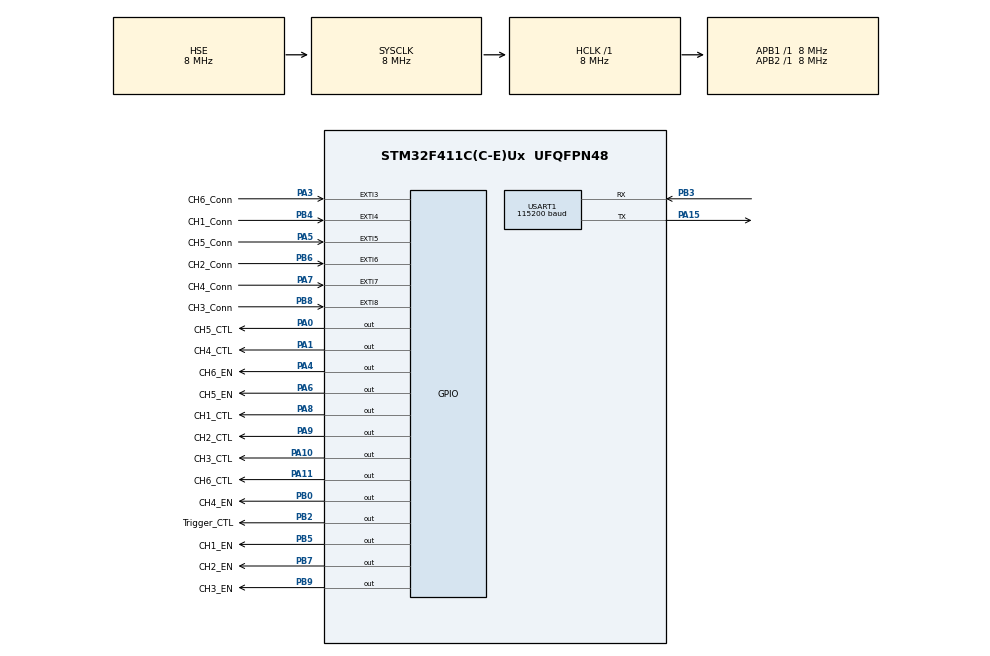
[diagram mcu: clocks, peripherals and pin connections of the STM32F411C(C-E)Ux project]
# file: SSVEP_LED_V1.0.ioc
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Mcu.Family=STM32F4
Mcu.Name=STM32F411C(C-E)Ux
Mcu.Package=UFQFPN48
NVIC.PriorityGroup=NVIC_PRIORITYGROUP_4
NVIC.TIM1_BRK_TIM9_IRQn=true\:2\:0\:true\:false\:true\:true\:true\:true
NVIC.TIM1_TRG_COM_TIM11_IRQn=true\:2\:0\:true\:false\:true\:true\:true\:true
NVIC.TIM1_UP_TIM10_IRQn=true\:2\:0\:true\:false\:true\:true\:true\:true
NVIC.TIM3_IRQn=true\:2\:0\:true\:false\:true\:true\:true\:true
NVIC.TIM4_IRQn=true\:2\:0\:true\:false\:true\:true\:true\:true
NVIC.TIM5_IRQn=true\:2\:0\:true\:false\:true\:true\:true\:true
NVIC.USART1_IRQn=true\:1\:0\:true\:false\:true\:true\:true\:true
PA0-WKUP.GPIO_Label=CH5_CTL
PA0-WKUP.GPIO_PuPd=GPIO_NOPULL
PA0-WKUP.GPIO_Speed=GPIO_SPEED_FREQ_VERY_HIGH
PA0-WKUP.PinState=GPIO_PIN_RESET
PA0-WKUP.Signal=GPIO_Output
PA1.GPIO_Label=CH4_CTL
PA1.GPIO_PuPd=GPIO_NOPULL
PA1.GPIO_Speed=GPIO_SPEED_FREQ_VERY_HIGH
PA1.Signal=GPIO_Output
PA10.GPIO_Label=CH3_CTL
PA10.GPIO_PuPd=GPIO_NOPULL
PA10.GPIO_Speed=GPIO_SPEED_FREQ_VERY_HIGH
PA10.Signal=GPIO_Output
PA11.GPIO_Label=CH6_CTL
PA11.GPIO_PuPd=GPIO_NOPULL
PA11.GPIO_Speed=GPIO_SPEED_FREQ_VERY_HIGH
PA11.Signal=GPIO_Output
PA13.Mode=Serial_Wire
PA13.Signal=SYS_JTMS-SWDIO
PA14.Mode=Serial_Wire
PA14.Signal=SYS_JTCK-SWCLK
PA15.Mode=Asynchronous
PA15.Signal=USART1_TX
PA3.GPIO_Label=CH6_Conn
PA3.GPIO_ModeDefaultEXTI=GPIO_MODE_IT_RISING_FALLING
PA3.GPIO_PuPd=GPIO_PULLUP
PA3.Signal=GPXTI3
PA4.GPIO_Label=CH6_EN
PA4.GPIO_PuPd=GPIO_PULLUP
PA4.GPIO_Speed=GPIO_SPEED_FREQ_HIGH
PA4.PinState=GPIO_PIN_SET
PA4.Signal=GPIO_Output
PA5.GPIO_Label=CH5_Conn
PA5.GPIO_ModeDefaultEXTI=GPIO_MODE_IT_RISING_FALLING
PA5.GPIO_PuPd=GPIO_PULLUP
PA5.Signal=GPXTI5
PA6.GPIO_Label=CH5_EN
PA6.GPIO_PuPd=GPIO_PULLUP
PA6.GPIO_Speed=GPIO_SPEED_FREQ_HIGH
PA6.PinState=GPIO_PIN_SET
PA6.Signal=GPIO_Output
PA7.GPIO_Label=CH4_Conn
PA7.GPIO_ModeDefaultEXTI=GPIO_MODE_IT_RISING_FALLING
PA7.GPIO_PuPd=GPIO_PULLUP
PA7.Signal=GPXTI7
PA8.GPIO_Label=CH1_CTL
PA8.GPIO_PuPd=GPIO_NOPULL
PA8.GPIO_Speed=GPIO_SPEED_FREQ_VERY_HIGH
PA8.Signal=GPIO_Output
PA9.GPIO_Label=CH2_CTL
PA9.GPIO_PuPd=GPIO_NOPULL
PA9.GPIO_Speed=GPIO_SPEED_FREQ_VERY_HIGH
PA9.Signal=GPIO_Output
PB0.GPIO_Label=CH4_EN
PB0.GPIO_PuPd=GPIO_PULLUP
PB0.GPIO_Speed=GPIO_SPEED_FREQ_HIGH
PB0.PinState=GPIO_PIN_SET
PB0.Signal=GPIO_Output
PB2.GPIO_Label=Trigger_CTL
PB2.GPIO_PuPd=GPIO_PULLDOWN
PB2.GPIO_Speed=GPIO_SPEED_FREQ_VERY_HIGH
PB2.Signal=GPIO_Output
PB3.Mode=Asynchronous
PB3.Signal=USART1_RX
PB4.GPIO_Label=CH1_Conn
PB4.GPIO_ModeDefaultEXTI=GPIO_MODE_IT_RISING_FALLING
PB4.GPIO_PuPd=GPIO_PULLUP
PB4.Signal=GPXTI4
PB5.GPIO_Label=CH1_EN
PB5.GPIO_PuPd=GPIO_PULLUP
PB5.GPIO_Speed=GPIO_SPEED_FREQ_HIGH
PB5.PinState=GPIO_PIN_SET
PB5.Signal=GPIO_Output
PB6.GPIO_Label=CH2_Conn
PB6.GPIO_ModeDefaultEXTI=GPIO_MODE_IT_RISING_FALLING
PB6.GPIO_PuPd=GPIO_PULLUP
PB6.Signal=GPXTI6
PB7.GPIO_Label=CH2_EN
PB7.GPIO_PuPd=GPIO_PULLUP
PB7.GPIO_Speed=GPIO_SPEED_FREQ_HIGH
PB7.PinState=GPIO_PIN_SET
PB7.Signal=GPIO_Output
PB8.GPIO_Label=CH3_Conn
PB8.GPIO_ModeDefaultEXTI=GPIO_MODE_IT_RISING_FALLING
PB8.GPIO_PuPd=GPIO_PULLUP
PB8.Signal=GPXTI8
PB9.GPIO_Label=CH3_EN
PB9.GPIO_PuPd=GPIO_PULLUP
PB9.GPIO_Speed=GPIO_SPEED_FREQ_HIGH
PB9.PinState=GPIO_PIN_SET
PB9.Signal=GPIO_Output
PH0\ -\ OSC_IN.Mode=HSE-External-Oscillator
PH0\ -\ OSC_IN.Signal=RCC_OSC_IN
PH1\ -\ OSC_OUT.Mode=HSE-External-Oscillator
PH1\ -\ OSC_OUT.Signal=RCC_OSC_OUT
ProjectManager.HeapSize=0x200
ProjectManager.StackSize=0x400
ProjectManager.TargetToolchain=MDK-ARM V5.32
RCC.48MHZClocksFreq_Value=25000000
RCC.AHBFreq_Value=8000000
RCC.APB1Freq_Value=8000000
RCC.APB1TimFreq_Value=8000000
RCC.APB2Freq_Value=8000000
RCC.APB2TimFreq_Value=8000000
RCC.CortexFreq_Value=8000000
RCC.HCLKFreq_Value=8000000
RCC.HSE_VALUE=8000000
RCC.HSI_VALUE=16000000
RCC.LSE_VALUE=32768
RCC.PLLM=8
RCC.PLLN=100
RCC.PLLSourceVirtual=RCC_PLLSOURCE_HSE
RCC.SYSCLKFreq_VALUE=8000000
RCC.SYSCLKSource=RCC_SYSCLKSOURCE_HSE
RCC.VCOOutputFreq_Value=100000000
TIM10.Prescaler=1220-1
TIM11.Prescaler=1220-1
TIM3.AutoReloadPreload=TIM_AUTORELOAD_PRELOAD_DISABLE
TIM3.ClockDivision=TIM_CLOCKDIVISION_DIV1
TIM3.Period=65535
TIM3.Prescaler=1220-1
TIM3.TIM_MasterOutputTrigger=TIM_TRGO_OC1
TIM4.Prescaler=1220-1
TIM4.TIM_MasterOutputTrigger=TIM_TRGO_OC1
TIM5.Period=65535
TIM5.Prescaler=1220-1
TIM5.TIM_MasterOutputTrigger=TIM_TRGO_OC1
TIM9.Prescaler=1220-1
USART1.BaudRate=115200
USART1.VirtualMode=VM_ASYNC
VP_TIM10_VS_ClockSourceINT.Mode=Enable_Timer
VP_TIM11_VS_ClockSourceINT.Mode=Enable_Timer
VP_TIM3_VS_ClockSourceINT.Mode=Internal
VP_TIM4_VS_ClockSourceINT.Mode=Internal
VP_TIM5_VS_ClockSourceINT.Mode=Internal
VP_TIM9_VS_ClockSourceINT.Mode=Internal
board=custom

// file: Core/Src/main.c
/* USER CODE BEGIN Header */
/**
  ******************************************************************************
  * @file           : main.c
  * @brief          : Main program body
  ******************************************************************************
  * @attention
  *
  * Copyright (c) 2023 STMicroelectronics.
  * All rights reserved.
  *
  * This software is licensed under terms that can be found in the LICENSE file
  * in the root directory of this software component.
  * If no LICENSE file comes with this software, it is provided AS-IS.
  *
  ******************************************************************************
  */
/* USER CODE END Header */
#include "main.h"
#include "tim.h"
#include "usart.h"
#include "gpio.h"

/* USER CODE BEGIN Includes */
#include "MainAdd.h"
/* USER CODE END Includes */

void SystemClock_Config(void);

int main(void)
{

  /* MCU Configuration--------------------------------------------------------*/

  /* Reset of all peripherals, Initializes the Flash interface and the Systick. */
  HAL_Init();

  /* Configure the system clock */
  SystemClock_Config();

  /* Initialize all configured peripherals */
  MX_GPIO_Init();
  MX_TIM3_Init();
  MX_TIM4_Init();
  MX_TIM5_Init();
  MX_TIM9_Init();
  MX_TIM10_Init();
  MX_TIM11_Init();
  MX_USART1_UART_Init();
  /* USER CODE BEGIN 2 */
  Main_Init_Add();
  /* USER CODE END 2 */

  /* Infinite loop */
  /* USER CODE BEGIN WHILE */
  while (1)
  {
	  Main_Loop_Add();
    /* USER CODE END WHILE */

  }
}

void SystemClock_Config(void)
{
  RCC_OscInitTypeDef RCC_OscInitStruct = {0};
  RCC_ClkInitTypeDef RCC_ClkInitStruct = {0};

  /** Configure the main internal regulator output voltage
  */
  __HAL_RCC_PWR_CLK_ENABLE();
  __HAL_PWR_VOLTAGESCALING_CONFIG(PWR_REGULATOR_VOLTAGE_SCALE1);

  /** Initializes the RCC Oscillators according to the specified parameters
  * in the RCC_OscInitTypeDef structure.
  */
  RCC_OscInitStruct.OscillatorType = RCC_OSCILLATORTYPE_HSE;
  RCC_OscInitStruct.HSEState = RCC_HSE_ON;
  RCC_OscInitStruct.PLL.PLLState = RCC_PLL_NONE;
  if (HAL_RCC_OscConfig(&RCC_OscInitStruct) != HAL_OK)
  {
    Error_Handler();
  }

  /** Initializes the CPU, AHB and APB buses clocks
  */
  RCC_ClkInitStruct.ClockType = RCC_CLOCKTYPE_HCLK|RCC_CLOCKTYPE_SYSCLK
                              |RCC_CLOCKTYPE_PCLK1|RCC_CLOCKTYPE_PCLK2;
  RCC_ClkInitStruct.SYSCLKSource = RCC_SYSCLKSOURCE_HSE;
  RCC_ClkInitStruct.AHBCLKDivider = RCC_SYSCLK_DIV1;
  RCC_ClkInitStruct.APB1CLKDivider = RCC_HCLK_DIV1;
  RCC_ClkInitStruct.APB2CLKDivider = RCC_HCLK_DIV1;

  if (HAL_RCC_ClockConfig(&RCC_ClkInitStruct, FLASH_LATENCY_0) != HAL_OK)
  {
    Error_Handler();
  }
}

void Error_Handler(void)
{
  __disable_irq();
  while (1)
  {
  }
}
